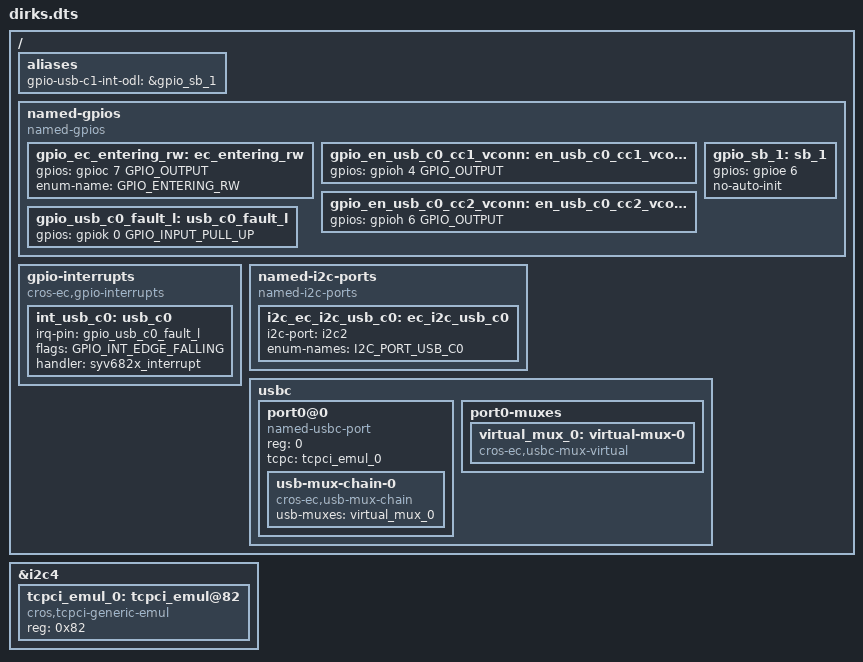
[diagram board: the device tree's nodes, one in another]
/* Copyright 2025 The ChromiumOS Authors
 * Use of this source code is governed by a BSD-style license that can be
 * found in the LICENSE file.
 */
#include <it8xxx2_emul.dts>

/ {
	aliases {
		gpio-usb-c1-int-odl = &gpio_sb_1;
	};

	named-gpios {
		compatible = "named-gpios";

		gpio_ec_entering_rw: ec_entering_rw {
			gpios = <&gpioc 7 GPIO_OUTPUT>;
			enum-name = "GPIO_ENTERING_RW";
		};
		gpio_en_usb_c0_cc1_vconn: en_usb_c0_cc1_vconn {
			gpios = <&gpioh 4 GPIO_OUTPUT>;
		};
		gpio_en_usb_c0_cc2_vconn: en_usb_c0_cc2_vconn {
			gpios = <&gpioh 6 GPIO_OUTPUT>;
		};
		gpio_usb_c0_fault_l: usb_c0_fault_l {
			gpios = <&gpiok 0 GPIO_INPUT_PULL_UP>;
		};
		gpio_sb_1: sb_1 {
			gpios = <&gpioe 6 0>;
			no-auto-init;
		};
	};

	gpio-interrupts {
		compatible = "cros-ec,gpio-interrupts";

		int_usb_c0: usb_c0 {
			irq-pin = <&gpio_usb_c0_fault_l>;
			flags = <GPIO_INT_EDGE_FALLING>;
			handler = "syv682x_interrupt";
		};
	};

	named-i2c-ports {
		compatible = "named-i2c-ports";

		i2c_ec_i2c_usb_c0: ec_i2c_usb_c0 {
			i2c-port = <&i2c2>;
			enum-names = "I2C_PORT_USB_C0";
		};
	};

	usbc {
		#address-cells = <1>;
		#size-cells = <0>;
		port0@0 {
			compatible = "named-usbc-port";
			reg = <0>;
			tcpc = <&tcpci_emul_0>;
			usb-mux-chain-0 {
				compatible = "cros-ec,usb-mux-chain";
				usb-muxes = <&virtual_mux_0>;
			};
		};
		port0-muxes {
			virtual_mux_0: virtual-mux-0 {
				compatible = "cros-ec,usbc-mux-virtual";
			};
		};
	};
};

&i2c4 {
	tcpci_emul_0: tcpci_emul@82 {
		compatible = "cros,tcpci-generic-emul";
		status = "okay";
		reg = <0x82>;
	};
};
